# PIC32MZ2064DAB288 device description
Architecture: MIPS; Family: PIC32MZDA; Series: PIC32MZ
Registers are 32-bit, read-write, no defined reset value unless marked. A register's access mark holds for its fields unless they carry their own. Offsets are from the block's base; [hi:lo] are bit positions; {n}, {i} and the like mark numbered series.

## CRYPTO
Instances: CRYPTO 0x1f8e5000 in periph_indep
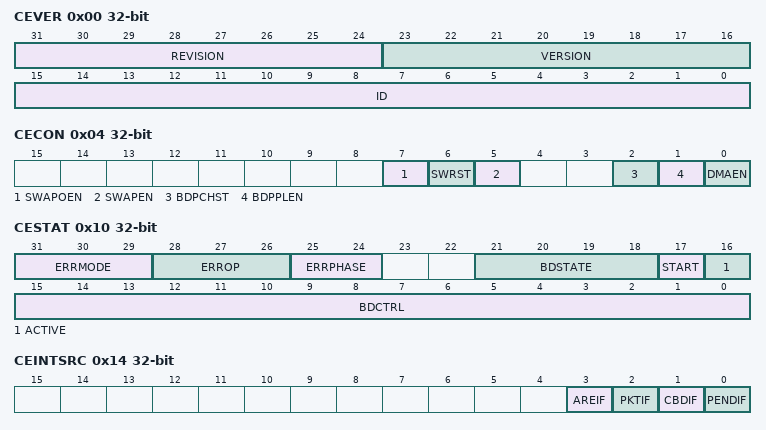
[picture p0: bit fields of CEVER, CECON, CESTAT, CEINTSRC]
0x00 CEVER ro — Crypto Engine Revision
  [31:24] REVISION, [23:16] VERSION, [15:0] ID
0x04 CECON — Crypto Engine Control Register
  [7] SWAPOEN — Swap Output Data Enable bit
    1=Output data is byte swapped when written by dedicated DMA; 0=Output data is not byte swapped when written by dedicated DMA
  [6] SWRST — Software Reset bit
    1=Initiate a software reset of the Crypto Engine; 0=Normal operation
  [5] SWAPEN — Input Data Swap Enable bit
    1=Input data is byte swapped when read by dedicated DMA; 0=Input data is not byte swapped when read by dedicated DMA
  [2] BDPCHST — Buffer Descriptor Processor Fetch Enable bit
    1=BDP descriptor fetch is enabled; 0=BDP descriptor fetch is disabled
  [1] BDPPLEN — Buffer Descriptor Processor Poll Enable bit
    1=Poll for descriptor until valid bit is set; 0=Do not poll
  [0] DMAEN — DMA Enable bit
    1=Crypto Engine DMA is enabled; 0=Crypto Engine DMA is disabled
0x08 CEBDADDR ro — Crypto Engine Buffer Descriptor Register
  [31:0] BDPADDR
0x0C CEBDPADDR ro — Crypto Engine Buffer Descriptor Processor Register
  [31:0] BASEADDR
0x10 CESTAT ro — Crypto Engine Status Register
  [31:29] ERRMODE — Internal Error Mode Status bits
    3=CEK operation; 2=KEK operation; 1=Preboot authentication; 0=Normal operation
  [28:26] ERROP — Internal Error Operation Status bits
    4=Authentication; 2=Decryption; 1=Encryption
  [25:24] ERRPHASE — Internal Error Phase of DMA Status bits
    3=Destination data; 2=Source data; 1=Security Association (SA) access; 0=Buffer Descriptor (BD) access
  [21:18] BDSTATE — Buffer Descriptor Processor State Status bits
    6=SA fetch; 5=Fetch BDP is disabled; 4=Descriptor is done; 3=Data phase; 2=BDP is loading; 1=Descriptor fetch request is pending; 0=BDP is idle
  [17] START — DMA Start Status bit
    1=DMA start has occurred; 0=DMA start has not occurred
  [16] ACTIVE — Buffer Descriptor Processor Status bit
    1=BDP is active; 0=BDP is idle
  [15:0] BDCTRL
0x14 CEINTSRC ro — Crypto Engine Interrupt Source Register
  [3] AREIF — Access Response Error Interrupt bit
    1=Error occurred trying to access memory outside the Crypto Engine; 0=No error has occurred
  [2] PKTIF — DMA Packet Completion Interrupt Status bit
    1=DMA packet was completed; 0=DMA packet was not completed
  [1] CBDIF — BD Transmit Status bit
    1=Last BD transmit was processed; 0=Last BD transmit has not been processed
  [0] PENDIF — Crypto Engine Interrupt Pending Status bit
    1=Crypto Engine interrupt is pending (this value is the result of an OR of all interrupts in the Crypto Engine); 0=Crypto Engine interrupt is not pending
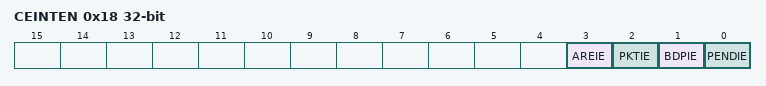
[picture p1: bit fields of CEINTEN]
0x18 CEINTEN — Crypto Engine Interrupt Enable Register
  [3] AREIE — Access Response Error Interrupt Enable bit
    1=Access response error interrupts are enabled; 0=Access response error interrupts are not enabled
  [2] PKTIE — DMA Packet Completion Interrupt Enable bit
    1=DMA packet completion interrupts are enabled; 0=DMA packet completion interrupts are not enabled
  [1] BDPIE — DMA Buffer Descriptor Processor Interrupt Enable bit
    1=BDP interrupts are enabled; 0=BDP interrupts are not enabled
  [0] PENDIE — Master Interrupt Enable bit
    1=Crypto Engine interrupts are enabled; 0=Crypto Engine interrupts are not enabled
0x1C CEPOLLCON — Crypto Engine Poll Control Register
  [15:0] BDPPLCON
0x20 CEHDLEN — Crypto Engine Header Length Register
  [7:0] HDRLEN
0x24 CETRLLEN — Crypto Engine Trailer Length Register
  [7:0] TRLRLEN

## CTMU
Instances: CTMU 0x1f84c200 in periph_pb3_std
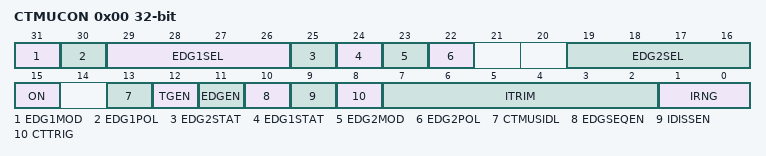
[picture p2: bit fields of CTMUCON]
0x00 CTMUCON — CTMU Control Register
  [31] EDG1MOD — Edge1 Edge Sampling Select bit
    1=Input is edge-sensitive; 0=Input is level-sensitive
  [30] EDG1POL — Edge 1 Polarity Select bit
    1=Edge1 programmed for a positive edge response; 0=Edge1 programmed for a negative edge response
  [29:26] EDG1SEL — Edge 1 Source Select bits
    14=C2OUT pin is selected; 13=C1OUT pin is selected; {v}=IC{v-6} Capture Event is selected (v=7..12); 6=OC4 Capture Event is selected; 5=OC3 Capture Event is selected; 4=OC2 Capture Event is selected; 3=CTED1 pin is selected; 2=CTED2 pin is selected; 1=OC1 Compare Event is selected; 0=Timer1 Event is selected
  [25] EDG2STAT — Edge2 Status bit
    1=Edge2 has occurred; 0=Edge2 has not occurred
  [24] EDG1STAT — Edge1 Status bit
    1=Edge1 has occurred; 0=Edge1 has not occurred
  [23] EDG2MOD — Edge2 Edge Sampling Select bit
    1=Input is edge-sensitive; 0=Input is level-sensitive
  [22] EDG2POL — Edge 2 Polarity Select bit
    1=Edge2 programmed for a positive edge response; 0=Edge2 programmed for a negative edge response
  [19:16] EDG2SEL — Edge 2 Source Select bits
    56=C2OUT pin is selected; 52=C1OUT pin is selected; 48=PBCLK3; 44=IC5 Capture Event is selected; 40=IC4 Capture Event is selected; 36=IC3 Capture Event is selected; 32=IC2 Capture Event is selected; 28=IC1 Capture Event is selected; 24=OC4 Capture Event is selected; 20=OC3 Capture Event is selected; 16=OC2 Capture Event is selected; 12=CTED1 pin is selected; 8=CTED2 pin is selected; 4=OC1 Compare Event is selected; 0=Timer1 Event is selected
  [15] ON — ON Enable bit
    1=Module is enabled; 0=Module is disabled
  [13] CTMUSIDL — Stop-in-Idle Mode bit
    1=Discontinue module operation when device enters Idle mode; 0=Continue module operation in Idle mode
  [12] TGEN — Time Generation Enable bit
    1=Enables edge delay generation; 0=Disables edge delay generation
  [11] EDGEN — Edge Enable bit
    1=Edges are not blocked; 0=Edges are blocked
  [10] EDGSEQEN — Edge Sequence Enable bit
    1=Edge1 must occur before Edge2 can occur; 0=No edge sequence is needed
  [9] IDISSEN — Analog Current Source Control bit
    1=Analog current source output is grounded; 0=Analog current source output is not grounded
  [8] CTTRIG — Trigger Control bit
    1=Trigger output is enabled; 0=Trigger output is disabled
  [7:2] ITRIM — Current Source Trim bits
    31=Maximum positive change from nominal current; 1=Minimum positive change from nominal current; 0=Nominal current output specified by IRNG; 63=Minimum negative change from nominal current; 33=Maximum negative change from nominal current
  [1:0] IRNG — Current Range Select bits
    3=100 times base current; 2=10 times base current; 1=Base current level; 0=1000 times base current(4)

## Notices in the file
Copyright (c) 2017 Microchip Technology Inc.
SPDX-License-Identifier: Apache-2.0
Licensed under the Apache License, Version 2.0 (the "License");
you may not use this file except in compliance with the License.
You may obtain a copy of the License at
http://www.apache.org/licenses/LICENSE-2.0
Unless required by applicable law or agreed to in writing, software
distributed under the License is distributed on an "AS IS" BASIS,
WITHOUT WARRANTIES OR CONDITIONS OF ANY KIND, either express or implied.
See the License for the specific language governing permissions and
limitations under the License.
